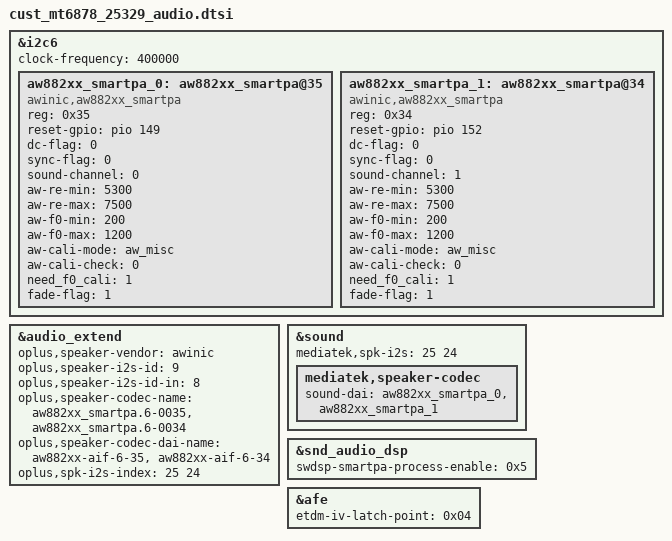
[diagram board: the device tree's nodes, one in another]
// SPDX-License-Identifier: GPL-2.0
/* Copyright (c) 2020 MediaTek Inc. */

&i2c6 {
	clock-frequency = <400000>;

	aw882xx_smartpa_0: aw882xx_smartpa@35 {
		compatible = "awinic,aw882xx_smartpa";
		#sound-dai-cells = <0>;
		reg = <0x35>;
		reset-gpio = <&pio 149 0>;
		dc-flag = <0>;
		sync-flag = <0>;
		sound-channel = <0>;
		aw-re-min = <5300>;
		aw-re-max = <7500>;
		aw-f0-min = <200>;
		aw-f0-max= <1200>;
		aw-cali-mode = "aw_misc";
		aw-cali-check = <0>;
		need_f0_cali = <1>;
		fade-flag = <1>;
		status = "okay";
	};

	aw882xx_smartpa_1: aw882xx_smartpa@34 {
		compatible = "awinic,aw882xx_smartpa";
		#sound-dai-cells = <0>;
		reg = <0x34>;
		reset-gpio = <&pio 152 0>;
		dc-flag = <0>;
		sync-flag = <0>;
		sound-channel = <1>;
		aw-re-min = <5300>;
		aw-re-max = <7500>;
		aw-f0-min = <200>;
		aw-f0-max= <1200>;
		aw-cali-mode = "aw_misc";
		aw-cali-check = <0>;
		need_f0_cali = <1>;
		fade-flag = <1>;
		status = "okay";
	};
};

&audio_extend {
	//for awinic speaker
	oplus,speaker-vendor = "awinic";
	oplus,speaker-i2s-id = <9>;
	oplus,speaker-i2s-id-in = <8>;
	oplus,speaker-codec-name = "aw882xx_smartpa.6-0035","aw882xx_smartpa.6-0034";
	oplus,speaker-codec-dai-name = "aw882xx-aif-6-35","aw882xx-aif-6-34";
	oplus,spk-i2s-index = <25 24>;
	status = "okay";
};

&sound {
	mediatek,spk-i2s = <25 24>;
	mediatek,speaker-codec {
		sound-dai = <&aw882xx_smartpa_0 &aw882xx_smartpa_1>;
	};
};

&snd_audio_dsp {
	swdsp-smartpa-process-enable = <0x5>;
};

&afe {
	etdm-iv-latch-point = <0x04>;
};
